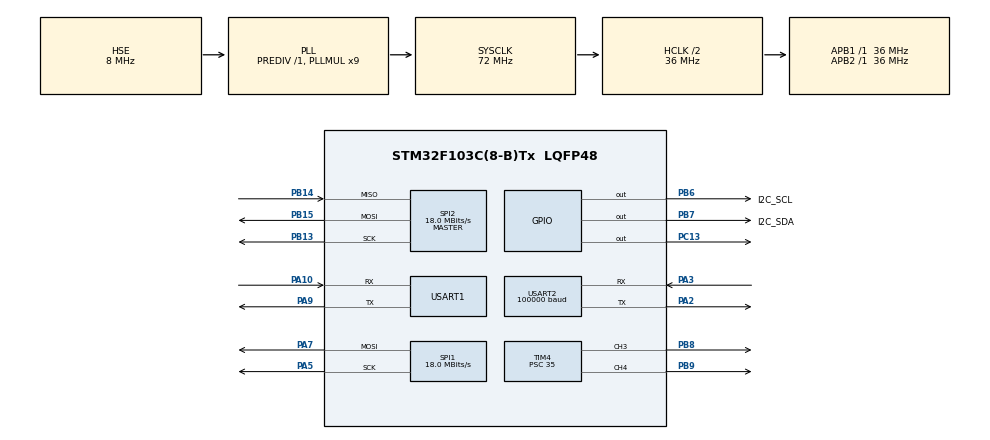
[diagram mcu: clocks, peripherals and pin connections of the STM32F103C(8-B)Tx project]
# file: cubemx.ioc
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Dma.Request0=USART2_RX
Dma.Request1=USART1_RX
Dma.Request2=USART1_TX
Dma.USART1_RX.1.Direction=DMA_PERIPH_TO_MEMORY
Dma.USART1_RX.1.Instance=DMA1_Channel5
Dma.USART1_RX.1.MemDataAlignment=DMA_MDATAALIGN_BYTE
Dma.USART1_RX.1.MemInc=DMA_MINC_ENABLE
Dma.USART1_RX.1.Mode=DMA_NORMAL
Dma.USART1_RX.1.PeriphDataAlignment=DMA_PDATAALIGN_BYTE
Dma.USART1_RX.1.PeriphInc=DMA_PINC_DISABLE
Dma.USART1_RX.1.Priority=DMA_PRIORITY_LOW
Dma.USART1_TX.2.Direction=DMA_MEMORY_TO_PERIPH
Dma.USART1_TX.2.Instance=DMA1_Channel4
Dma.USART1_TX.2.MemDataAlignment=DMA_MDATAALIGN_BYTE
Dma.USART1_TX.2.MemInc=DMA_MINC_ENABLE
Dma.USART1_TX.2.Mode=DMA_NORMAL
Dma.USART1_TX.2.PeriphDataAlignment=DMA_PDATAALIGN_BYTE
Dma.USART1_TX.2.PeriphInc=DMA_PINC_DISABLE
Dma.USART1_TX.2.Priority=DMA_PRIORITY_LOW
Dma.USART2_RX.0.Direction=DMA_PERIPH_TO_MEMORY
Dma.USART2_RX.0.Instance=DMA1_Channel6
Dma.USART2_RX.0.MemDataAlignment=DMA_MDATAALIGN_BYTE
Dma.USART2_RX.0.MemInc=DMA_MINC_ENABLE
Dma.USART2_RX.0.Mode=DMA_NORMAL
Dma.USART2_RX.0.PeriphDataAlignment=DMA_PDATAALIGN_BYTE
Dma.USART2_RX.0.PeriphInc=DMA_PINC_DISABLE
Dma.USART2_RX.0.Priority=DMA_PRIORITY_LOW
Mcu.Family=STM32F1
Mcu.Name=STM32F103C(8-B)Tx
Mcu.Package=LQFP48
NVIC.DMA1_Channel4_IRQn=true\:0\:0\:false\:false\:true\:false\:true\:true
NVIC.DMA1_Channel5_IRQn=true\:0\:0\:false\:false\:true\:false\:true\:true
NVIC.DMA1_Channel6_IRQn=true\:0\:0\:false\:false\:true\:false\:true\:true
NVIC.PriorityGroup=NVIC_PRIORITYGROUP_4
NVIC.SPI1_IRQn=true\:0\:0\:false\:false\:true\:true\:true\:true
NVIC.SPI2_IRQn=true\:0\:0\:false\:false\:true\:true\:true\:true
NVIC.TIM3_IRQn=true\:15\:0\:false\:false\:true\:false\:true\:true
NVIC.TimeBase=TIM3_IRQn
NVIC.TimeBaseIP=TIM3
NVIC.USART1_IRQn=true\:0\:0\:false\:false\:true\:true\:true\:true
NVIC.USART2_IRQn=true\:0\:0\:false\:false\:true\:true\:true\:true
PA10.Mode=Asynchronous
PA10.Signal=USART1_RX
PA13.Mode=Serial_Wire
PA13.Signal=SYS_JTMS-SWDIO
PA14.Mode=Serial_Wire
PA14.Signal=SYS_JTCK-SWCLK
PA2.Mode=Asynchronous
PA2.Signal=USART2_TX
PA3.Mode=Asynchronous
PA3.Signal=USART2_RX
PA5.Mode=TX_Only_Simplex_Unidirect_Master
PA5.Signal=SPI1_SCK
PA7.Mode=TX_Only_Simplex_Unidirect_Master
PA7.Signal=SPI1_MOSI
PA9.Mode=Asynchronous
PA9.Signal=USART1_TX
PB13.Mode=Full_Duplex_Master
PB13.Signal=SPI2_SCK
PB14.Mode=Full_Duplex_Master
PB14.Signal=SPI2_MISO
PB15.Mode=Full_Duplex_Master
PB15.Signal=SPI2_MOSI
PB6.GPIO_Label=I2C_SCL
PB6.Signal=GPIO_Output
PB7.GPIO_Label=I2C_SDA
PB7.Signal=GPIO_Output
PB8.Signal=S_TIM4_CH3
PB9.Signal=S_TIM4_CH4
PC13-TAMPER-RTC.GPIO_ModeDefaultOutputPP=GPIO_MODE_OUTPUT_PP
PC13-TAMPER-RTC.GPIO_PuPd=GPIO_PULLDOWN
PC13-TAMPER-RTC.Signal=GPIO_Output
PC14-OSC32_IN.Mode=LSE-External-Oscillator
PC14-OSC32_IN.Signal=RCC_OSC32_IN
PC15-OSC32_OUT.Mode=LSE-External-Oscillator
PC15-OSC32_OUT.Signal=RCC_OSC32_OUT
PD0-OSC_IN.Mode=HSE-External-Oscillator
PD0-OSC_IN.Signal=RCC_OSC_IN
PD1-OSC_OUT.Mode=HSE-External-Oscillator
PD1-OSC_OUT.Signal=RCC_OSC_OUT
ProjectManager.HeapSize=0x200
ProjectManager.StackSize=0x400
ProjectManager.TargetToolchain=Makefile
RCC.AHBCLKDivider=RCC_SYSCLK_DIV2
RCC.AHBFreq_Value=36000000
RCC.APB1Freq_Value=36000000
RCC.APB1TimFreq_Value=36000000
RCC.APB2Freq_Value=36000000
RCC.APB2TimFreq_Value=36000000
RCC.EnbaleCSS=true
RCC.HCLKFreq_Value=36000000
RCC.PLLMUL=RCC_PLL_MUL9
RCC.PLLSourceVirtual=RCC_PLLSOURCE_HSE
RCC.SYSCLKFreq_VALUE=72000000
RCC.SYSCLKSource=RCC_SYSCLKSOURCE_PLLCLK
RCC.USBFreq_Value=72000000
SH.S_TIM4_CH3.0=TIM4_CH3,PWM Generation3 CH3
SH.S_TIM4_CH4.0=TIM4_CH4,PWM Generation4 CH4
SPI1.CalculateBaudRate=18.0 MBits/s
SPI1.Direction=SPI_DIRECTION_2LINES
SPI1.Mode=SPI_MODE_MASTER
SPI1.VirtualType=VM_MASTER
SPI2.CalculateBaudRate=18.0 MBits/s
SPI2.Direction=SPI_DIRECTION_2LINES
SPI2.Mode=SPI_MODE_MASTER
SPI2.VirtualType=VM_MASTER
TIM4.Channel-PWM\ Generation3\ CH3=TIM_CHANNEL_3
TIM4.Channel-PWM\ Generation4\ CH4=TIM_CHANNEL_4
TIM4.OC3Preload_PWM=ENABLE
TIM4.Period=20480
TIM4.Prescaler=35
USART1.VirtualMode=VM_ASYNC
USART2.BaudRate=100000
USART2.Mode=MODE_RX
USART2.Parity=PARITY_EVEN
USART2.StopBits=STOPBITS_2
USART2.VirtualMode=VM_ASYNC
VP_SYS_VS_tim3.Mode=TIM3
board=custom

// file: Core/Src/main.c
/* USER CODE BEGIN Header */
/**
 ******************************************************************************
 * @file           : main.c
 * @brief          : Main program body
 ******************************************************************************
 * @attention
 *
 * <h2><center>&copy; Copyright (c) 2021 STMicroelectronics.
 * All rights reserved.</center></h2>
 *
 * This software component is licensed by ST under BSD 3-Clause license,
 * the "License"; You may not use this file except in compliance with the
 * License. You may obtain a copy of the License at:
 *                        opensource.org/licenses/BSD-3-Clause
 *
 ******************************************************************************
 */
/* USER CODE END Header */
#include "main.h"
#include "dma.h"
#include "spi.h"
#include "tim.h"
#include "usart.h"
#include "gpio.h"

/* USER CODE BEGIN Includes */
#include "appMain.h"
/* USER CODE END Includes */

void SystemClock_Config(void);

int main(void)
{

  /* MCU Configuration--------------------------------------------------------*/

  /* Reset of all peripherals, Initializes the Flash interface and the Systick. */
  HAL_Init();

  /* Configure the system clock */
  SystemClock_Config();

  /* Initialize all configured peripherals */
  MX_GPIO_Init();
  MX_DMA_Init();
  MX_USART1_UART_Init();
  MX_TIM4_Init();
  MX_USART2_UART_Init();
  MX_SPI1_Init();
  MX_SPI2_Init();
  /* USER CODE BEGIN 2 */
  appMain();
  /* USER CODE END 2 */

  /* Infinite loop */
  while (1)
  {

  }
}

void SystemClock_Config(void)
{
  RCC_OscInitTypeDef RCC_OscInitStruct = {0};
  RCC_ClkInitTypeDef RCC_ClkInitStruct = {0};

  /** Initializes the RCC Oscillators according to the specified parameters
   * in the RCC_OscInitTypeDef structure.
   */
  RCC_OscInitStruct.OscillatorType = RCC_OSCILLATORTYPE_HSE;
  RCC_OscInitStruct.HSEState = RCC_HSE_ON;
  RCC_OscInitStruct.HSEPredivValue = RCC_HSE_PREDIV_DIV1;
  RCC_OscInitStruct.HSIState = RCC_HSI_ON;
  RCC_OscInitStruct.PLL.PLLState = RCC_PLL_ON;
  RCC_OscInitStruct.PLL.PLLSource = RCC_PLLSOURCE_HSE;
  RCC_OscInitStruct.PLL.PLLMUL = RCC_PLL_MUL9;
  if (HAL_RCC_OscConfig(&RCC_OscInitStruct) != HAL_OK)
  {
    Error_Handler();
  }

  /** Initializes the CPU, AHB and APB buses clocks
   */
  RCC_ClkInitStruct.ClockType = RCC_CLOCKTYPE_HCLK | RCC_CLOCKTYPE_SYSCLK | RCC_CLOCKTYPE_PCLK1 | RCC_CLOCKTYPE_PCLK2;
  RCC_ClkInitStruct.SYSCLKSource = RCC_SYSCLKSOURCE_PLLCLK;
  RCC_ClkInitStruct.AHBCLKDivider = RCC_SYSCLK_DIV2;
  RCC_ClkInitStruct.APB1CLKDivider = RCC_HCLK_DIV1;
  RCC_ClkInitStruct.APB2CLKDivider = RCC_HCLK_DIV1;

  if (HAL_RCC_ClockConfig(&RCC_ClkInitStruct, FLASH_LATENCY_2) != HAL_OK)
  {
    Error_Handler();
  }

  /** Enables the Clock Security System
   */
  HAL_RCC_EnableCSS();
}

void HAL_TIM_PeriodElapsedCallback(TIM_HandleTypeDef *htim)
{
  if (htim->Instance == TIM3)
  {
    HAL_IncTick();
  }
}

void Error_Handler(void)
{
  __disable_irq();
  while (1)
  {
  }
}
